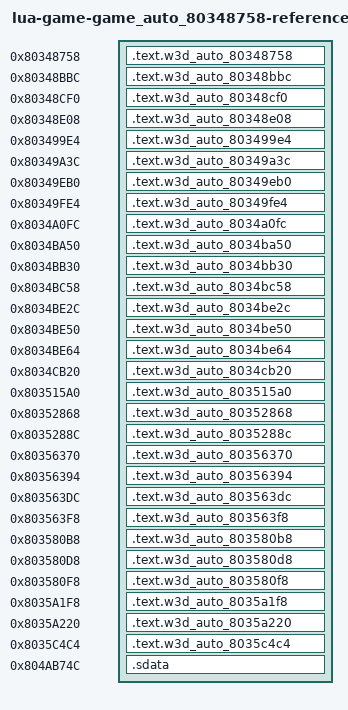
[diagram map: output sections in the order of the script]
/* Generated reference-only placements. All bodies are source-built. */
OUTPUT_FORMAT("elf32-powerpc")
OUTPUT_ARCH(powerpc)
ENTRY(w3d_auto_80348758)
_SDA_BASE_ = 0x804b2540;
_SDA2_BASE_ = 0x804c2540;
fn_801A1E48 = 0x801a1e48;
fn_801A2360 = 0x801a2360;
fn_801A360C = 0x801a360c;
fn_801EDE8C = 0x801ede8c;
fn_80210AFC = 0x80210afc;
SECTIONS {
  .text.w3d_auto_80348758 0x80348758 : { *(.text.w3d_auto_80348758) }
  .text.w3d_auto_80348bbc 0x80348bbc : { *(.text.w3d_auto_80348bbc) }
  .text.w3d_auto_80348cf0 0x80348cf0 : { *(.text.w3d_auto_80348cf0) }
  .text.w3d_auto_80348e08 0x80348e08 : { *(.text.w3d_auto_80348e08) }
  .text.w3d_auto_803499e4 0x803499e4 : { *(.text.w3d_auto_803499e4) }
  .text.w3d_auto_80349a3c 0x80349a3c : { *(.text.w3d_auto_80349a3c) }
  .text.w3d_auto_80349eb0 0x80349eb0 : { *(.text.w3d_auto_80349eb0) }
  .text.w3d_auto_80349fe4 0x80349fe4 : { *(.text.w3d_auto_80349fe4) }
  .text.w3d_auto_8034a0fc 0x8034a0fc : { *(.text.w3d_auto_8034a0fc) }
  .text.w3d_auto_8034ba50 0x8034ba50 : { *(.text.w3d_auto_8034ba50) }
  .text.w3d_auto_8034bb30 0x8034bb30 : { *(.text.w3d_auto_8034bb30) }
  .text.w3d_auto_8034bc58 0x8034bc58 : { *(.text.w3d_auto_8034bc58) }
  .text.w3d_auto_8034be2c 0x8034be2c : { *(.text.w3d_auto_8034be2c) }
  .text.w3d_auto_8034be50 0x8034be50 : { *(.text.w3d_auto_8034be50) }
  .text.w3d_auto_8034be64 0x8034be64 : { *(.text.w3d_auto_8034be64) }
  .text.w3d_auto_8034cb20 0x8034cb20 : { *(.text.w3d_auto_8034cb20) }
  .text.w3d_auto_803515a0 0x803515a0 : { *(.text.w3d_auto_803515a0) }
  .text.w3d_auto_80352868 0x80352868 : { *(.text.w3d_auto_80352868) }
  .text.w3d_auto_8035288c 0x8035288c : { *(.text.w3d_auto_8035288c) }
  .text.w3d_auto_80356370 0x80356370 : { *(.text.w3d_auto_80356370) }
  .text.w3d_auto_80356394 0x80356394 : { *(.text.w3d_auto_80356394) }
  .text.w3d_auto_803563dc 0x803563dc : { *(.text.w3d_auto_803563dc) }
  .text.w3d_auto_803563f8 0x803563f8 : { *(.text.w3d_auto_803563f8) }
  .text.w3d_auto_803580b8 0x803580b8 : { *(.text.w3d_auto_803580b8) }
  .text.w3d_auto_803580d8 0x803580d8 : { *(.text.w3d_auto_803580d8) }
  .text.w3d_auto_803580f8 0x803580f8 : { *(.text.w3d_auto_803580f8) }
  .text.w3d_auto_8035a1f8 0x8035a1f8 : { *(.text.w3d_auto_8035a1f8) }
  .text.w3d_auto_8035a220 0x8035a220 : { *(.text.w3d_auto_8035a220) }
  .text.w3d_auto_8035c4c4 0x8035c4c4 : { *(.text.w3d_auto_8035c4c4) }
  .sdata 0x804ab74c (NOLOAD) : {
    . = 0x0; lbl_804AB74C = .;
    . += 1; }
  /DISCARD/ : { *(.text*) *(.rodata*) *(.data*) *(.bss*) *(.sdata*) *(.sbss*) *(.comment) }
}
